# STM32L162ZDT6 register map
File version: 1.0
STM32L162QCH6,STM32L162QDH3,STM32L162QDH6,STM32L162QDH7,STM32L162RCT6A,STM32L162RDT6,STM32L162RDY6,STM32L162VCT6A,STM32L162VDT6,STM32L162ZCT6,STM32L162ZDT6
Registers are 32-bit, access not given, reset 0x0 unless marked. A register's access mark holds for its fields unless they carry their own. Offsets are from the block's base; lines under a group give offsets from that group; [hi:lo] are bit positions; {n}, {i} and the like mark numbered series; 'fields as' and 'values as' point back to an identical list; <NAME> marks a mode.

## Memory map
0x1FF80000 OB
0x40000000 TIM2
0x40000400 TIM3
0x40000800 TIM4
0x40000C00 TIM5
0x40001000 TIM6
0x40001400 TIM7
0x40002400 LCD
0x40002800 RTC
0x40002C00 WWDG
0x40003000 IWDG
0x40003800 SPI2
0x40003C00 SPI3
0x40004400 USART2
0x40004800 USART3
0x40004C00 UART4
0x40005000 UART5
0x40005400 I2C1
0x40005800 I2C2
0x40005C00 USB
0x40007000 PWR
0x40007400 DAC1
0x40007C00 COMP
0x40007C00 COMP1
0x40007C00 COMP12_COMMON
0x40007C01 COMP2
0x40007C04 RI
0x40007C5C OPAMP
0x40007C5C OPAMP1
0x40007C5C OPAMP123_COMMON
0x40007C5D OPAMP2
0x40007C5E OPAMP3
0x40010000 SYSCFG
0x40010400 EXTI
0x40010800 TIM9
0x40010C00 TIM10
0x40011000 TIM11
0x40012400 ADC1
0x40012C00 SDIO
0x40013000 SPI1
0x40013800 USART1
0x40020000 GPIOA
0x40020400 GPIOB
0x40020800 GPIOC
0x40020C00 GPIOD
0x40021000 GPIOE
0x40021400 GPIOH
0x40021800 GPIOF
0x40021C00 GPIOG
0x40023000 CRC
0x40023800 RCC
0x40023C00 FLASH
0x40026000 DMA1
0x40026400 DMA2
0x50060000 AES
0xA0000000 FSMC_Bank1
0xA0000104 FSMC_Bank1E
0xE0042000 DBGMCU

## OB
Base 0x1FF80000
0x00 RDP
0x04 USER
0x08 WRP01
0x0C WRP23
0x10 WRP45
0x14 WRP67
0x18 WRP89
0x1C WRP1011

## TIM2
Base 0x40000000
Same registers: TIM3 0x40000400, TIM4 0x40000800, TIM5 0x40000C00, TIM6 0x40001000, TIM7 0x40001400, TIM9 0x40010800, TIM10 0x40010C00, TIM11 0x40011000
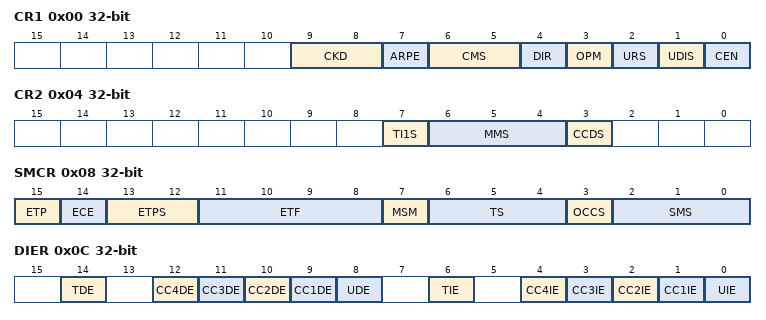
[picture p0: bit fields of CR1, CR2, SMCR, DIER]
0x00 CR1
  [9:8] CKD, [7] ARPE, [6:5] CMS, [4] DIR, [3] OPM, [2] URS, [1] UDIS, [0] CEN
0x04 CR2
  [7] TI1S, [6:4] MMS, [3] CCDS
0x08 SMCR
  [15] ETP, [14] ECE, [13:12] ETPS, [11:8] ETF, [7] MSM, [6:4] TS, [3] OCCS, [2:0] SMS
0x0C DIER
  [14] TDE, [n+8] CC{n}DE (n=1..4), [8] UDE, [6] TIE, [n] CC{n}IE (n=1..4), [0] UIE
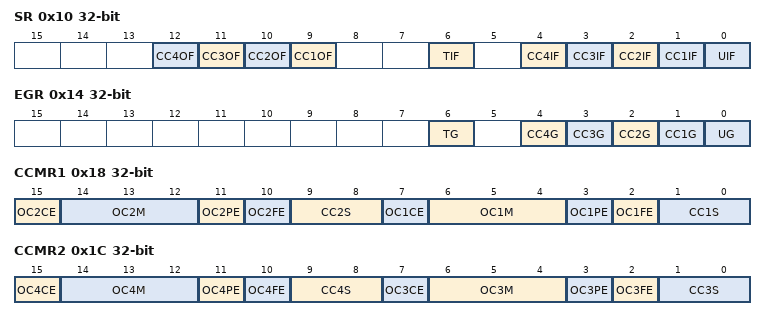
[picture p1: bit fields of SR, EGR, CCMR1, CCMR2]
0x10 SR
  [n+8] CC{n}OF (n=1..4), [6] TIF, [n] CC{n}IF (n=1..4), [0] UIF
0x14 EGR
  [6] TG, [n] CC{n}G (n=1..4), [0] UG
0x18 CCMR1
  [15] OC2CE, [14:12] OC2M, [11] OC2PE, [10] OC2FE, [9:8] CC2S, [7] OC1CE, [6:4] OC1M, [3] OC1PE, [2] OC1FE, [1:0] CC1S
0x1C CCMR2
  [15] OC4CE, [14:12] OC4M, [11] OC4PE, [10] OC4FE, [9:8] CC4S, [7] OC3CE, [6:4] OC3M, [3] OC3PE, [2] OC3FE, [1:0] CC3S
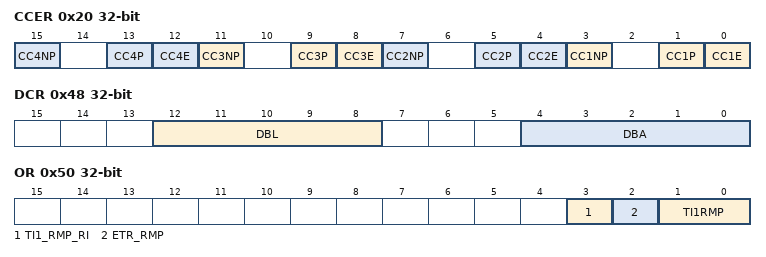
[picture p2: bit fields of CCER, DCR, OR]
0x20 CCER
  [4n-1] CC{n}NP (n=1..4), [4n-3] CC{n}P (n=1..4), [4n-4] CC{n}E (n=1..4)
0x24 CNT
0x28 PSC
  [15:0] PSC
0x2C ARR
{0x30+4i} CCR{i} (i=1..4)
  [15:0] CCR{i}
0x48 DCR
  [12:8] DBL, [4:0] DBA
0x4C DMAR
  [15:0] DMAB
0x50 OR
  [3] TI1_RMP_RI, [2] ETR_RMP, [1:0] TI1RMP

## LCD
Base 0x40002400
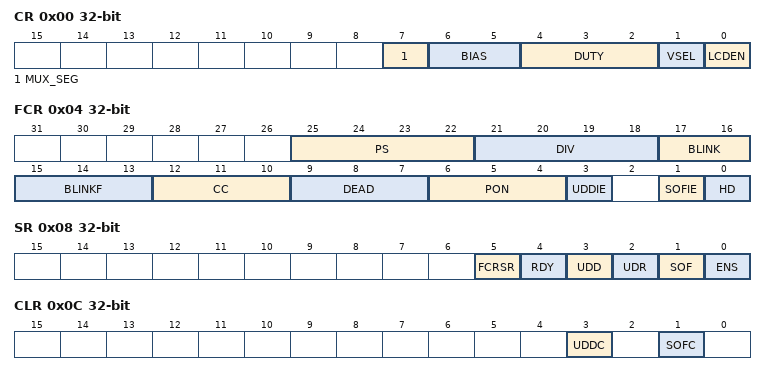
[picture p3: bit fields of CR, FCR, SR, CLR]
0x00 CR
  [7] MUX_SEG, [6:5] BIAS, [4:2] DUTY, [1] VSEL, [0] LCDEN
0x04 FCR
  [25:22] PS, [21:18] DIV, [17:16] BLINK, [15:13] BLINKF, [12:10] CC, [9:7] DEAD, [6:4] PON, [3] UDDIE, [1] SOFIE, [0] HD
0x08 SR
  [5] FCRSR, [4] RDY, [3] UDD, [2] UDR, [1] SOF, [0] ENS
0x0C CLR
  [3] UDDC, [1] SOFC
0x14 RAM.0
  [31:0] SEGMENT_DATA
0x18 RAM.1
  [31:0] SEGMENT_DATA
0x1C RAM.2
  [31:0] SEGMENT_DATA
0x20 RAM.3
  [31:0] SEGMENT_DATA
0x24 RAM.4
  [31:0] SEGMENT_DATA
0x28 RAM.5
  [31:0] SEGMENT_DATA
0x2C RAM.6
  [31:0] SEGMENT_DATA
0x30 RAM.7
  [31:0] SEGMENT_DATA
0x34 RAM.8
  [31:0] SEGMENT_DATA
0x38 RAM.9
  [31:0] SEGMENT_DATA
0x3C RAM.10
  [31:0] SEGMENT_DATA
0x40 RAM.11
  [31:0] SEGMENT_DATA
0x44 RAM.12
  [31:0] SEGMENT_DATA
0x48 RAM.13
  [31:0] SEGMENT_DATA
0x4C RAM.14
  [31:0] SEGMENT_DATA
0x50 RAM.15
  [31:0] SEGMENT_DATA

## RTC
Base 0x40002800
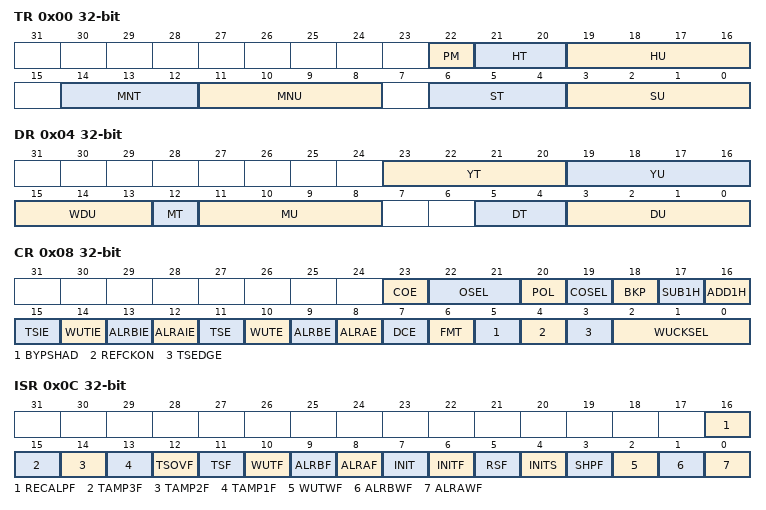
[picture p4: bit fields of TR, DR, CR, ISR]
0x00 TR
  [22] PM, [21:20] HT, [19:16] HU, [14:12] MNT, [11:8] MNU, [6:4] ST, [3:0] SU
0x04 DR
  [23:20] YT, [19:16] YU, [15:13] WDU, [12] MT, [11:8] MU, [5:4] DT, [3:0] DU
0x08 CR
  [23] COE, [22:21] OSEL, [20] POL, [19] COSEL, [18] BKP, [17] SUB1H, [16] ADD1H, [15] TSIE, [14] WUTIE, [13] ALRBIE, [12] ALRAIE, [11] TSE, [10] WUTE, [9] ALRBE, [8] ALRAE, [7] DCE, [6] FMT, [5] BYPSHAD, [4] REFCKON, [3] TSEDGE, [2:0] WUCKSEL
0x0C ISR
  [16] RECALPF, [15] TAMP3F, [14] TAMP2F, [13] TAMP1F, [12] TSOVF, [11] TSF, [10] WUTF, [9] ALRBF, [8] ALRAF, [7] INIT, [6] INITF, [5] RSF, [4] INITS, [3] SHPF, [2] WUTWF, [1] ALRBWF, [0] ALRAWF
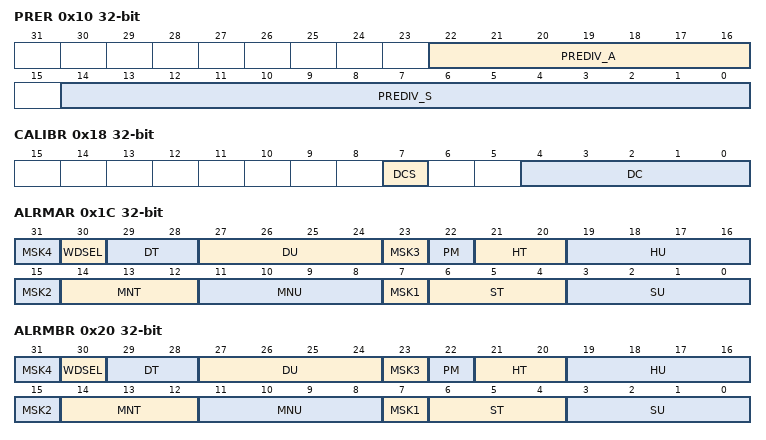
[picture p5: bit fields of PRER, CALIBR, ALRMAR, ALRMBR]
0x10 PRER
  [22:16] PREDIV_A, [14:0] PREDIV_S
0x14 WUTR
  [15:0] WUT
0x18 CALIBR
  [7] DCS, [4:0] DC
0x1C ALRMAR
  [8n-1] MSK{n} (n=1..4), [30] WDSEL, [29:28] DT, [27:24] DU, [22] PM, [21:20] HT, [19:16] HU, [14:12] MNT, [11:8] MNU, [6:4] ST, [3:0] SU
0x20 ALRMBR
  fields as ALRMAR
0x24 WPR
  [7:0] KEY
0x28 SSR
  [15:0] SS
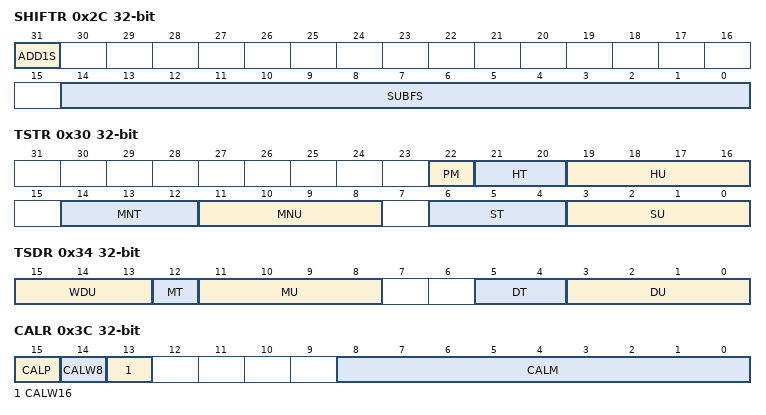
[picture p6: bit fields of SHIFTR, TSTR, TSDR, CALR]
0x2C SHIFTR
  [31] ADD1S, [14:0] SUBFS
0x30 TSTR
  fields as TR
0x34 TSDR
  [15:13] WDU, [12] MT, [11:8] MU, [5:4] DT, [3:0] DU
0x38 TSSSR
  [15:0] SS
0x3C CALR
  [15] CALP, [14] CALW8, [13] CALW16, [8:0] CALM
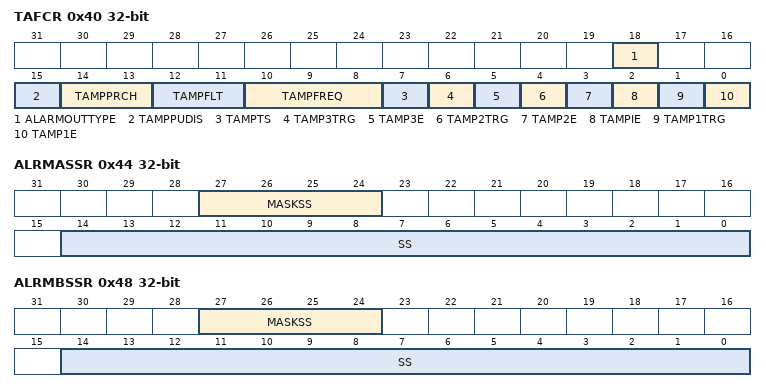
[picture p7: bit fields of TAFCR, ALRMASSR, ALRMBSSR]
0x40 TAFCR
  [18] ALARMOUTTYPE, [15] TAMPPUDIS, [14:13] TAMPPRCH, [12:11] TAMPFLT, [10:8] TAMPFREQ, [7] TAMPTS, [6] TAMP3TRG, [5] TAMP3E, [4] TAMP2TRG, [3] TAMP2E, [2] TAMPIE, [1] TAMP1TRG, [0] TAMP1E
0x44 ALRMASSR
  [27:24] MASKSS, [14:0] SS
0x48 ALRMBSSR
  [27:24] MASKSS, [14:0] SS
{0x50+4i} BKP{i}R (i=0..31)
